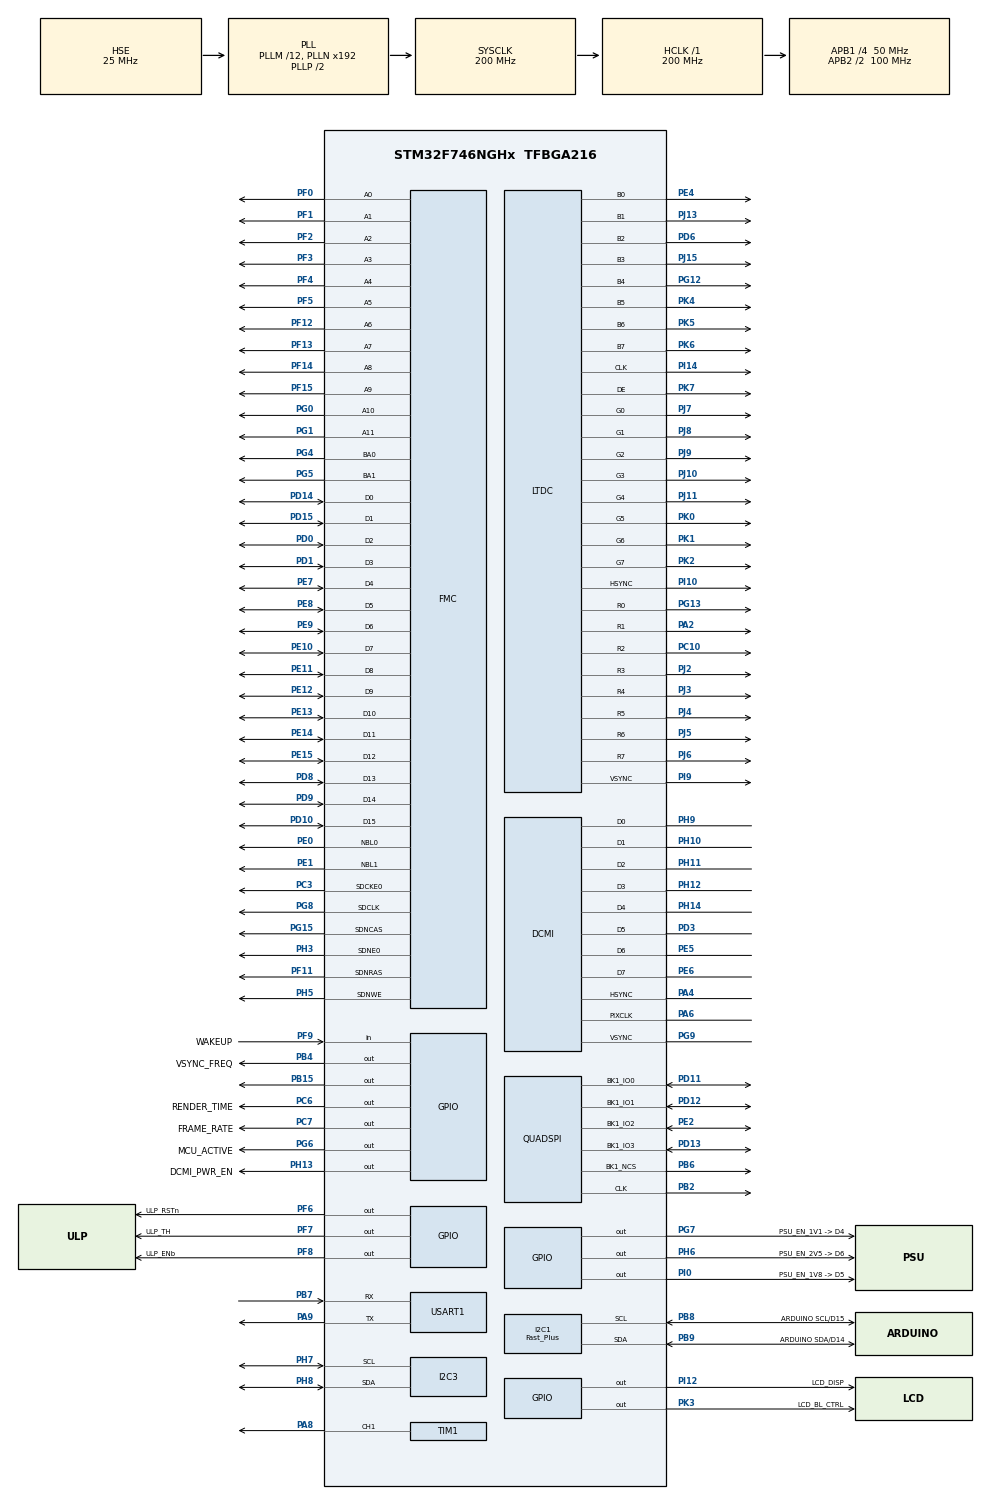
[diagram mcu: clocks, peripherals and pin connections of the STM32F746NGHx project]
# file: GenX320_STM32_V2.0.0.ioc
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CORTEX_M7.ART_ACCLERATOR_ENABLE=1
CORTEX_M7.AccessPermission-Cortex_Memory_Protection_Unit_Region0_Settings=MPU_REGION_FULL_ACCESS
CORTEX_M7.AccessPermission-Cortex_Memory_Protection_Unit_Region1_Settings=MPU_REGION_FULL_ACCESS
CORTEX_M7.BaseAddress-Cortex_Memory_Protection_Unit_Region0_Settings=0x90000000
CORTEX_M7.BaseAddress-Cortex_Memory_Protection_Unit_Region1_Settings=0x90000000
CORTEX_M7.CPU_DCache=Enabled
CORTEX_M7.CPU_ICache=Enabled
CORTEX_M7.Enable-Cortex_Memory_Protection_Unit_Region0_Settings=MPU_REGION_ENABLE
CORTEX_M7.Enable-Cortex_Memory_Protection_Unit_Region1_Settings=MPU_REGION_ENABLE
CORTEX_M7.IsCacheable-Cortex_Memory_Protection_Unit_Region1_Settings=MPU_ACCESS_CACHEABLE
CORTEX_M7.MPU_Control=MPU_PRIVILEGED_DEFAULT
CORTEX_M7.PREFETCH_ENABLE=1
CORTEX_M7.Size-Cortex_Memory_Protection_Unit_Region0_Settings=MPU_REGION_SIZE_256MB
CORTEX_M7.Size-Cortex_Memory_Protection_Unit_Region1_Settings=MPU_REGION_SIZE_16MB
DCMI.HSPolarity=DCMI_HSPOLARITY_HIGH
DCMI.JPEGMode=DCMI_JPEG_ENABLE
DCMI.VSPolarity=DCMI_VSPOLARITY_HIGH
Dma.DCMI.0.Direction=DMA_PERIPH_TO_MEMORY
Dma.DCMI.0.FIFOMode=DMA_FIFOMODE_ENABLE
Dma.DCMI.0.FIFOThreshold=DMA_FIFO_THRESHOLD_FULL
Dma.DCMI.0.Instance=DMA2_Stream1
Dma.DCMI.0.MemBurst=DMA_MBURST_INC4
Dma.DCMI.0.MemDataAlignment=DMA_MDATAALIGN_WORD
Dma.DCMI.0.MemInc=DMA_MINC_ENABLE
Dma.DCMI.0.Mode=DMA_CIRCULAR
Dma.DCMI.0.PeriphBurst=DMA_PBURST_SINGLE
Dma.DCMI.0.PeriphDataAlignment=DMA_PDATAALIGN_WORD
Dma.DCMI.0.PeriphInc=DMA_PINC_DISABLE
Dma.DCMI.0.Priority=DMA_PRIORITY_HIGH
Dma.MEMTOMEM.1.Direction=DMA_MEMORY_TO_MEMORY
Dma.MEMTOMEM.1.FIFOMode=DMA_FIFOMODE_ENABLE
Dma.MEMTOMEM.1.FIFOThreshold=DMA_FIFO_THRESHOLD_FULL
Dma.MEMTOMEM.1.Instance=DMA2_Stream0
Dma.MEMTOMEM.1.MemBurst=DMA_MBURST_INC4
Dma.MEMTOMEM.1.MemDataAlignment=DMA_MDATAALIGN_WORD
Dma.MEMTOMEM.1.MemInc=DMA_MINC_ENABLE
Dma.MEMTOMEM.1.Mode=DMA_NORMAL
Dma.MEMTOMEM.1.PeriphBurst=DMA_PBURST_INC4
Dma.MEMTOMEM.1.PeriphDataAlignment=DMA_PDATAALIGN_WORD
Dma.MEMTOMEM.1.PeriphInc=DMA_PINC_DISABLE
Dma.MEMTOMEM.1.Priority=DMA_PRIORITY_LOW
Dma.Request0=DCMI
Dma.Request1=MEMTOMEM
FMC.CASLatency1=FMC_SDRAM_CAS_LATENCY_3
FMC.ExitSelfRefreshDelay1=7
FMC.LoadToActiveDelay1=2
FMC.RCDDelay1=2
FMC.RPDelay1=2
FMC.ReadBurst1=FMC_SDRAM_RBURST_ENABLE
FMC.RowCycleDelay1=7
FMC.SDClockPeriod1=FMC_SDRAM_CLOCK_PERIOD_2
FMC.SelfRefreshTime1=4
FMC.WriteRecoveryTime1=3
FREERTOS.BinarySemaphores01=Vsync_Semaphore,Dynamic,NULL;ESP_LPW_Semph,Dynamic,NULL;Activity_Map_Semph,Dynamic,NULL;Statistics_Semph,Dynamic,NULL;Led_Tracking_Semph,Dynamic,NULL
FREERTOS.Mutexes01=tskCtlUpdateFb,Static,TskCtlUpdateFbControlBlock
FREERTOS.Tasks01=ESP_LPW,24,256,ESP_LPW_Task,Default,NULL,Dynamic,NULL,NULL;TouchGFXTask,26,4096,TouchGFX_Task,As external,NULL,Dynamic,NULL,NULL;Update_Fb,32,512,Task_Update_Fb,Default,&args_update_fb,Dynamic,NULL,NULL;Event_Decoding,27,256,Event_Decoding_Task,Default,&args_evt_decoder,Dynamic,NULL,NULL;Activity_Map,25,256,Activity_Map_Task,Default,NULL,Dynamic,NULL,NULL;Statistics,25,256,Statistics_Task,Default,NULL,Dynamic,NULL,NULL;Led_Tracking,25,256,Led_Tracking_Task,Default,NULL,Dynamic,NULL,NULL
FREERTOS.configTOTAL_HEAP_SIZE=75000
FREERTOS.configUSE_APPLICATION_TASK_TAG=1
FREERTOS.configUSE_IDLE_HOOK=0
FREERTOS.configUSE_NEWLIB_REENTRANT=1
I2C1.I2C_Speed_Mode=I2C_Fast_Plus
I2C1.Speed=1000
I2C1.Timing=0x0020081F
I2C3.Timing=0x00C0EAFF
LTDC.ActiveH=272
LTDC.ActiveW=480
LTDC.Alpha_L0=255
LTDC.Alpha_L1=255
LTDC.BlendingFactor1_L0=LTDC_BLENDING_FACTOR1_CA
LTDC.BlendingFactor1_L1=LTDC_BLENDING_FACTOR1_PAxCA
LTDC.BlendingFactor2_L0=LTDC_BLENDING_FACTOR2_CA
LTDC.BlendingFactor2_L1=LTDC_BLENDING_FACTOR2_PAxCA
LTDC.DEPolarity=LTDC_DEPOLARITY_AH
LTDC.FBStartAdress_L0=0xC0000000
LTDC.FBStartAdress_L1=(uint32_t)frame_buffer_l1_one
LTDC.Green_L1=0
LTDC.HBP=43
LTDC.HFP=8
LTDC.HSync=4
LTDC.ImageHeight_L0=272
LTDC.ImageHeight_L1=272
LTDC.ImageWidth_L0=480
LTDC.ImageWidth_L1=320
LTDC.Layers=0
LTDC.PixelFormat_L0=LTDC_PIXEL_FORMAT_ARGB8888
LTDC.VBP=12
LTDC.VFP=12
LTDC.VSPolarity=LTDC_VSPOLARITY_AH
LTDC.VSync=2
LTDC.WindowX0_L1=160
LTDC.WindowX1_L0=480
LTDC.WindowX1_L1=480
LTDC.WindowY1_L0=272
LTDC.WindowY1_L1=272
Mcu.Family=STM32F7
Mcu.Name=STM32F746NGHx
Mcu.Package=TFBGA216
NVIC.DCMI_IRQn=true\:5\:0\:false\:false\:true\:true\:true\:true\:true
NVIC.DMA2D_IRQn=true\:5\:0\:true\:false\:true\:true\:true\:true\:true
NVIC.DMA2_Stream0_IRQn=true\:5\:0\:false\:false\:true\:true\:true\:true\:true
NVIC.DMA2_Stream1_IRQn=true\:5\:0\:false\:false\:true\:true\:false\:true\:true
NVIC.I2C1_EV_IRQn=true\:5\:0\:false\:false\:true\:true\:true\:true\:true
NVIC.LTDC_ER_IRQn=true\:5\:0\:false\:false\:true\:true\:true\:true\:true
NVIC.LTDC_IRQn=true\:5\:0\:false\:false\:true\:true\:true\:true\:true
NVIC.PriorityGroup=NVIC_PRIORITYGROUP_4
NVIC.TIM6_DAC_IRQn=true\:15\:0\:false\:false\:true\:false\:false\:true\:true
NVIC.TimeBase=TIM6_DAC_IRQn
NVIC.TimeBaseIP=TIM6
NVIC.USART1_IRQn=true\:5\:0\:false\:false\:true\:true\:true\:true\:true
PA13.Mode=Serial_Wire
PA13.Signal=SYS_JTMS-SWDIO
PA14.Mode=Serial_Wire
PA14.Signal=SYS_JTCK-SWCLK
PA15.Signal=S_TIM2_CH1_ETR
PA2.Mode=RGB888
PA2.Signal=LTDC_R1
PA4.GPIO_Speed=GPIO_SPEED_FREQ_VERY_HIGH
PA4.Mode=Slave_8_bits_External_Synchro
PA4.Signal=DCMI_HSYNC
PA6.GPIO_Speed=GPIO_SPEED_FREQ_VERY_HIGH
PA6.Mode=Slave_8_bits_External_Synchro
PA6.Signal=DCMI_PIXCLK
PA8.GPIO_Speed=GPIO_SPEED_FREQ_HIGH
PA8.Signal=S_TIM1_CH1
PA9.GPIO_Speed=GPIO_SPEED_FREQ_LOW
PA9.Mode=Asynchronous
PA9.Signal=USART1_TX
PB15.Signal=GPIO_Output
PB2.Mode=Single Bank 1
PB2.Signal=QUADSPI_CLK
PB4.GPIO_Label=VSYNC_FREQ
PB4.GPIO_Speed=GPIO_SPEED_FREQ_VERY_HIGH
PB4.Signal=GPIO_Output
PB6.Mode=Single Bank 1
PB6.Signal=QUADSPI_BK1_NCS
PB7.GPIO_Speed=GPIO_SPEED_FREQ_LOW
PB7.Mode=Asynchronous
PB7.Signal=USART1_RX
PB8.GPIO_Label=ARDUINO SCL/D15
PB8.GPIO_Pu=GPIO_PULLUP
PB8.Mode=I2C
PB8.Signal=I2C1_SCL
PB9.GPIO_Label=ARDUINO SDA/D14
PB9.GPIO_Pu=GPIO_PULLUP
PB9.Mode=I2C
PB9.Signal=I2C1_SDA
PC10.Mode=RGB888
PC10.Signal=LTDC_R2
PC3.Mode=SdramChipSelect1_1
PC3.Signal=FMC_SDCKE0
PC6.GPIO_Label=RENDER_TIME
PC6.GPIO_Speed=GPIO_SPEED_FREQ_VERY_HIGH
PC6.Signal=GPIO_Output
PC7.GPIO_Label=FRAME_RATE
PC7.GPIO_Speed=GPIO_SPEED_FREQ_VERY_HIGH
PC7.Signal=GPIO_Output
PD0.Signal=FMC_D2_DA2
PD1.Signal=FMC_D3_DA3
PD10.Signal=FMC_D15_DA15
PD11.Mode=Single Bank 1
PD11.Signal=QUADSPI_BK1_IO0
PD12.Mode=Single Bank 1
PD12.Signal=QUADSPI_BK1_IO1
PD13.Mode=Single Bank 1
PD13.Signal=QUADSPI_BK1_IO3
PD14.Signal=FMC_D0_DA0
PD15.Signal=FMC_D1_DA1
PD3.GPIO_Speed=GPIO_SPEED_FREQ_VERY_HIGH
PD3.Mode=Slave_8_bits_External_Synchro
PD3.Signal=DCMI_D5
PD6.Mode=RGB888
PD6.Signal=LTDC_B2
PD8.Signal=FMC_D13_DA13
PD9.Signal=FMC_D14_DA14
PE0.Signal=FMC_NBL0
PE1.Signal=FMC_NBL1
PE10.Signal=FMC_D7_DA7
PE11.Signal=FMC_D8_DA8
PE12.Signal=FMC_D9_DA9
PE13.Signal=FMC_D10_DA10
PE14.Signal=FMC_D11_DA11
PE15.Signal=FMC_D12_DA12
PE2.Mode=Single Bank 1
PE2.Signal=QUADSPI_BK1_IO2
PE4.Mode=RGB888
PE4.Signal=LTDC_B0
PE5.GPIO_Speed=GPIO_SPEED_FREQ_VERY_HIGH
PE5.Mode=Slave_8_bits_External_Synchro
PE5.Signal=DCMI_D6
PE6.GPIO_Speed=GPIO_SPEED_FREQ_VERY_HIGH
PE6.Mode=Slave_8_bits_External_Synchro
PE6.Signal=DCMI_D7
PE7.Signal=FMC_D4_DA4
PE8.Signal=FMC_D5_DA5
PE9.Signal=FMC_D6_DA6
PF0.Signal=FMC_A0
PF1.Signal=FMC_A1
PF11.Signal=FMC_SDNRAS
PF12.Signal=FMC_A6
PF13.Signal=FMC_A7
PF14.Signal=FMC_A8
PF15.Signal=FMC_A9
PF2.Signal=FMC_A2
PF3.Signal=FMC_A3
PF4.Signal=FMC_A4
PF5.Signal=FMC_A5
PF6.GPIO_Label=ULP_RSTn
PF6.PinState=GPIO_PIN_SET
PF6.Signal=GPIO_Output
PF7.GPIO_Label=ULP_TH
PF7.PinState=GPIO_PIN_SET
PF7.Signal=GPIO_Output
PF8.GPIO_Label=ULP_ENb
PF8.PinState=GPIO_PIN_SET
PF8.Signal=GPIO_Output
PF9.GPIO_Label=WAKEUP
PF9.Signal=GPIO_Input
PG0.Signal=FMC_A10
PG1.Signal=FMC_A11
PG12.Mode=RGB888
PG12.Signal=LTDC_B4
PG13.Mode=RGB888
PG13.Signal=LTDC_R0
PG15.Signal=FMC_SDNCAS
PG4.Signal=FMC_A14_BA0
PG5.Signal=FMC_A15_BA1
PG6.GPIO_Label=MCU_ACTIVE
PG6.GPIO_Speed=GPIO_SPEED_FREQ_VERY_HIGH
PG6.Signal=GPIO_Output
PG7.GPIO_Label=PSU_EN_1V1 -> D4
PG7.Signal=GPIO_Output
PG8.Signal=FMC_SDCLK
PG9.GPIO_Speed=GPIO_SPEED_FREQ_VERY_HIGH
PG9.Mode=Slave_8_bits_External_Synchro
PG9.Signal=DCMI_VSYNC
PH0/OSC_IN.Mode=HSE-External-Oscillator
PH0/OSC_IN.Signal=RCC_OSC_IN
PH1/OSC_OUT.Mode=HSE-External-Oscillator
PH1/OSC_OUT.Signal=RCC_OSC_OUT
PH10.GPIO_Speed=GPIO_SPEED_FREQ_VERY_HIGH
PH10.Mode=Slave_8_bits_External_Synchro
PH10.Signal=DCMI_D1
PH11.GPIO_Speed=GPIO_SPEED_FREQ_VERY_HIGH
PH11.Mode=Slave_8_bits_External_Synchro
PH11.Signal=DCMI_D2
PH12.GPIO_Speed=GPIO_SPEED_FREQ_VERY_HIGH
PH12.Mode=Slave_8_bits_External_Synchro
PH12.Signal=DCMI_D3
PH13.GPIO_Label=DCMI_PWR_EN
PH13.Signal=GPIO_Output
PH14.GPIO_Speed=GPIO_SPEED_FREQ_VERY_HIGH
PH14.Mode=Slave_8_bits_External_Synchro
PH14.Signal=DCMI_D4
PH3.Mode=SdramChipSelect1_1
PH3.Signal=FMC_SDNE0
PH5.Signal=FMC_SDNWE
PH6.GPIO_Label=PSU_EN_2V5 -> D6
PH6.Signal=GPIO_Output
PH7.GPIO_Pu=GPIO_PULLUP
PH7.Mode=I2C
PH7.Signal=I2C3_SCL
PH8.GPIO_Pu=GPIO_PULLUP
PH8.Mode=I2C
PH8.Signal=I2C3_SDA
PH9.GPIO_Speed=GPIO_SPEED_FREQ_VERY_HIGH
PH9.Mode=Slave_8_bits_External_Synchro
PH9.Signal=DCMI_D0
PI0.GPIO_Label=PSU_EN_1V8 -> D5
PI0.Signal=GPIO_Output
PI10.Mode=RGB888
PI10.Signal=LTDC_HSYNC
PI12.GPIO_Label=LCD_DISP
PI12.PinState=GPIO_PIN_SET
PI12.Signal=GPIO_Output
PI14.Mode=RGB888
PI14.Signal=LTDC_CLK
PI9.Mode=RGB888
PI9.Signal=LTDC_VSYNC
PJ10.Mode=RGB888
PJ10.Signal=LTDC_G3
PJ11.Mode=RGB888
PJ11.Signal=LTDC_G4
PJ13.Mode=RGB888
PJ13.Signal=LTDC_B1
PJ15.Mode=RGB888
PJ15.Signal=LTDC_B3
PJ2.Mode=RGB888
PJ2.Signal=LTDC_R3
PJ3.Mode=RGB888
PJ3.Signal=LTDC_R4
PJ4.Mode=RGB888
PJ4.Signal=LTDC_R5
PJ5.Mode=RGB888
PJ5.Signal=LTDC_R6
PJ6.Mode=RGB888
PJ6.Signal=LTDC_R7
PJ7.Mode=RGB888
PJ7.Signal=LTDC_G0
PJ8.Mode=RGB888
PJ8.Signal=LTDC_G1
PJ9.Mode=RGB888
PJ9.Signal=LTDC_G2
PK0.Mode=RGB888
PK0.Signal=LTDC_G5
PK1.Mode=RGB888
PK1.Signal=LTDC_G6
PK2.Mode=RGB888
PK2.Signal=LTDC_G7
PK3.GPIO_Label=LCD_BL_CTRL
PK3.PinState=GPIO_PIN_SET
PK3.Signal=GPIO_Output
PK4.Mode=RGB888
PK4.Signal=LTDC_B5
PK5.Mode=RGB888
PK5.Signal=LTDC_B6
PK6.Mode=RGB888
PK6.Signal=LTDC_B7
PK7.Mode=RGB888
PK7.Signal=LTDC_DE
ProjectManager.HeapSize=0xA00
ProjectManager.StackSize=0xA00
ProjectManager.TargetToolchain=STM32CubeIDE
QUADSPI.ChipSelectHighTime=QSPI_CS_HIGH_TIME_6_CYCLE
QUADSPI.ClockPrescaler=1
QUADSPI.FifoThreshold=4
QUADSPI.FlashSize=24
QUADSPI.SampleShifting=QSPI_SAMPLE_SHIFTING_HALFCYCLE
RCC.AHBFreq_Value=200000000
RCC.APB1CLKDivider=RCC_HCLK_DIV4
RCC.APB1Freq_Value=50000000
RCC.APB1TimFreq_Value=100000000
RCC.APB2CLKDivider=RCC_HCLK_DIV2
RCC.APB2Freq_Value=100000000
RCC.APB2TimFreq_Value=200000000
RCC.CortexFreq_Value=200000000
RCC.HCLKFreq_Value=200000000
RCC.HSE_VALUE=25000000
RCC.HSI_VALUE=16000000
RCC.LSE_VALUE=32768
RCC.PLLI2SN=100
RCC.PLLM=12
RCC.PLLSAIN=50
RCC.PLLSAIRDiv=RCC_PLLSAIDIVR_4
RCC.PLLSourceVirtual=RCC_PLLSOURCE_HSE
RCC.SYSCLKFreq_VALUE=200000000
RCC.SYSCLKSource=RCC_SYSCLKSOURCE_PLLCLK
RCC.USBFreq_Value=200000000
RCC.VCOOutputFreq_Value=400000000
SH.FMC_A0.0=FMC_A0,12b-sda1
SH.FMC_A1.0=FMC_A1,12b-sda1
SH.FMC_A10.0=FMC_A10,12b-sda1
SH.FMC_A11.0=FMC_A11,12b-sda1
SH.FMC_A14_BA0.0=FMC_BA0,FourSdramBanks1
SH.FMC_A15_BA1.0=FMC_BA1,FourSdramBanks1
SH.FMC_A2.0=FMC_A2,12b-sda1
SH.FMC_A3.0=FMC_A3,12b-sda1
SH.FMC_A4.0=FMC_A4,12b-sda1
SH.FMC_A5.0=FMC_A5,12b-sda1
SH.FMC_A6.0=FMC_A6,12b-sda1
SH.FMC_A7.0=FMC_A7,12b-sda1
SH.FMC_A8.0=FMC_A8,12b-sda1
SH.FMC_A9.0=FMC_A9,12b-sda1
SH.FMC_D0_DA0.0=FMC_D0,sd-16b-d1
SH.FMC_D10_DA10.0=FMC_D10,sd-16b-d1
SH.FMC_D11_DA11.0=FMC_D11,sd-16b-d1
SH.FMC_D12_DA12.0=FMC_D12,sd-16b-d1
SH.FMC_D13_DA13.0=FMC_D13,sd-16b-d1
SH.FMC_D14_DA14.0=FMC_D14,sd-16b-d1
SH.FMC_D15_DA15.0=FMC_D15,sd-16b-d1
SH.FMC_D1_DA1.0=FMC_D1,sd-16b-d1
SH.FMC_D2_DA2.0=FMC_D2,sd-16b-d1
SH.FMC_D3_DA3.0=FMC_D3,sd-16b-d1
SH.FMC_D4_DA4.0=FMC_D4,sd-16b-d1
SH.FMC_D5_DA5.0=FMC_D5,sd-16b-d1
SH.FMC_D6_DA6.0=FMC_D6,sd-16b-d1
SH.FMC_D7_DA7.0=FMC_D7,sd-16b-d1
SH.FMC_D8_DA8.0=FMC_D8,sd-16b-d1
SH.FMC_D9_DA9.0=FMC_D9,sd-16b-d1
SH.FMC_NBL0.0=FMC_NBL0,Sd2ByteEnable1
SH.FMC_NBL1.0=FMC_NBL1,Sd2ByteEnable1
SH.FMC_SDCLK.0=FMC_SDCLK,12b-sda1
SH.FMC_SDNCAS.0=FMC_SDNCAS,12b-sda1
SH.FMC_SDNRAS.0=FMC_SDNRAS,12b-sda1
SH.FMC_SDNWE.0=FMC_SDNWE,12b-sda1
SH.S_TIM1_CH1.0=TIM1_CH1,PWM Generation1 CH1
SH.S_TIM2_CH1_ETR.0=TIM2_CH1
STMicroelectronics.X-CUBE-TOUCHGFX.4.22.1.ApplicationCcGraphicsJjApplication=TouchGFXOoGenerator
STMicroelectronics.X-CUBE-TOUCHGFX.4.22.1.tgfx_address1=0xC0000000
STMicroelectronics.X-CUBE-TOUCHGFX.4.22.1.tgfx_address2=0xC003FC00
STMicroelectronics.X-CUBE-TOUCHGFX.4.22.1.tgfx_buffering_strategy=Double
STMicroelectronics.X-CUBE-TOUCHGFX.4.22.1.tgfx_display_interface=disp_ltdc
STMicroelectronics.X-CUBE-TOUCHGFX.4.22.1.tgfx_hardware_accelerator=dma_2d
STMicroelectronics.X-CUBE-TOUCHGFX.4.22.1.tgfx_location=Allocate
STMicroelectronics.X-CUBE-TOUCHGFX.4.22.1.tgfx_vector_rendering=Disabled
STMicroelectronics.X-CUBE-TOUCHGFX.4.22.1.tgfx_video=Disabled
STMicroelectronics.X-CUBE-TOUCHGFX.4.22.1.tgfx_video_buffer_format=RGB565\:2
STMicroelectronics.X-CUBE-TOUCHGFX.4.22.1.tgfx_video_height=272
STMicroelectronics.X-CUBE-TOUCHGFX.4.22.1.tgfx_video_strategy=2
STMicroelectronics.X-CUBE-TOUCHGFX.4.22.1.tgfx_video_width=480
STMicroelectronics.X-CUBE-TOUCHGFX.4.22.1.tgfx_vsync=vsync_ltdc
TIM1.Channel-PWM\ Generation1\ CH1=TIM_CHANNEL_1
TIM1.OCFastMode_PWM-PWM\ Generation1\ CH1=TIM_OCFAST_ENABLE
TIM1.Period=9
TIM1.Prescaler=1
TIM1.Pulse-PWM\ Generation1\ CH1=5
TIM2.Period=4294967295
TIM2.Prescaler=99
USART1.VirtualMode-Asynchronous=VM_ASYNC
VP_CRC_VS_CRC.Mode=CRC_Activate
VP_DMA2D_VS_DMA2D.Mode=DMA2D_Activate
VP_FREERTOS_VS_CMSIS_V2.Mode=CMSIS_V2
VP_STMicroelectronics.X-CUBE-TOUCHGFX_VS_GraphicsJjApplication_4.22.1.Mode=GraphicsJjApplication
VP_SYS_VS_tim6.Mode=TIM6
VP_TIM1_VS_ClockSourceINT.Mode=Internal
VP_TIM2_VS_ClockSourceINT.Mode=Internal
board=custom

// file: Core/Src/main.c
/* USER CODE BEGIN Header */
/**
 ******************************************************************************
 * @file           : main.c
 * @brief          : Main program body
 ******************************************************************************
 * @attention
 *
 * <h2><center>&copy; Copyright (c) 2020 STMicroelectronics.
 * All rights reserved.</center></h2>
 *
 * This software component is licensed by ST under Ultimate Liberty license
 * SLA0044, the "License"; You may not use this file except in compliance with
 * the License. You may obtain a copy of the License at:
 *                             www.st.com/SLA0044
 *
 ******************************************************************************
 */
/* USER CODE END Header */
#include "main.h"
#include "cmsis_os.h"
#include "app_touchgfx.h"

/* USER CODE BEGIN Includes */
#include <stm32746g_discovery_qspi.h>
#include <touchgfx/hal/Config.hpp>

/* USER CODE END Includes */

typedef StaticSemaphore_t osStaticMutexDef_t;

/* USER CODE BEGIN PD */

#define REFRESH_COUNT        1835

#define SDRAM_TIMEOUT                            ((uint32_t)0xFFFF)
#define SDRAM_MODEREG_BURST_LENGTH_1             ((uint16_t)0x0000)
#define SDRAM_MODEREG_BURST_LENGTH_2             ((uint16_t)0x0001)
#define SDRAM_MODEREG_BURST_LENGTH_4             ((uint16_t)0x0002)
#define SDRAM_MODEREG_BURST_LENGTH_8             ((uint16_t)0x0004)
#define SDRAM_MODEREG_BURST_TYPE_SEQUENTIAL      ((uint16_t)0x0000)
#define SDRAM_MODEREG_BURST_TYPE_INTERLEAVED     ((uint16_t)0x0008)
#define SDRAM_MODEREG_CAS_LATENCY_2              ((uint16_t)0x0020)
#define SDRAM_MODEREG_CAS_LATENCY_3              ((uint16_t)0x0030)
#define SDRAM_MODEREG_OPERATING_MODE_STANDARD    ((uint16_t)0x0000)
#define SDRAM_MODEREG_WRITEBURST_MODE_PROGRAMMED ((uint16_t)0x0000)
#define SDRAM_MODEREG_WRITEBURST_MODE_SINGLE     ((uint16_t)0x0200)

#define PUTCHAR_PROTOTYPE int __io_putchar(int ch)
#define STATIC_HEAP_SIZE (1024)
#define ALIGN_FLOOR(addr, type) (((uint32_t)(addr)) & ~(uint32_t)(sizeof(type)-1))
#define ALIGN_CEIL(addr, type)   ALIGN_FLOOR((uint32_t)(addr) + sizeof(type) - 1, type)

/* USER CODE END PD */

CRC_HandleTypeDef hcrc;

DCMI_HandleTypeDef hdcmi;
DMA_HandleTypeDef hdma_dcmi;

DMA2D_HandleTypeDef hdma2d;

I2C_HandleTypeDef hi2c1;
I2C_HandleTypeDef hi2c3;

LTDC_HandleTypeDef hltdc;

QSPI_HandleTypeDef hqspi;

TIM_HandleTypeDef htim1;
TIM_HandleTypeDef htim2;

UART_HandleTypeDef huart1;

DMA_HandleTypeDef hdma_memtomem_dma2_stream0;
SDRAM_HandleTypeDef hsdram1;

/* Definitions for ESP_LPW */
osThreadId_t ESP_LPWHandle;
const osThreadAttr_t ESP_LPW_attributes = {
  .name = "ESP_LPW",
  .stack_size = 256 * 4,
  .priority = (osPriority_t) osPriorityNormal,
};
/* Definitions for TouchGFXTask */
osThreadId_t TouchGFXTaskHandle;
const osThreadAttr_t TouchGFXTask_attributes = {
  .name = "TouchGFXTask",
  .stack_size = 4096 * 4,
  .priority = (osPriority_t) osPriorityNormal2,
};
/* Definitions for Update_Fb */
osThreadId_t Update_FbHandle;
const osThreadAttr_t Update_Fb_attributes = {
  .name = "Update_Fb",
  .stack_size = 512 * 4,
  .priority = (osPriority_t) osPriorityAboveNormal,
};
/* Definitions for Event_Decoding */
osThreadId_t Event_DecodingHandle;
const osThreadAttr_t Event_Decoding_attributes = {
  .name = "Event_Decoding",
  .stack_size = 256 * 4,
  .priority = (osPriority_t) osPriorityNormal3,
};
/* Definitions for Activity_Map */
osThreadId_t Activity_MapHandle;
const osThreadAttr_t Activity_Map_attributes = {
  .name = "Activity_Map",
  .stack_size = 256 * 4,
  .priority = (osPriority_t) osPriorityNormal1,
};
/* Definitions for Statistics */
osThreadId_t StatisticsHandle;
const osThreadAttr_t Statistics_attributes = {
  .name = "Statistics",
  .stack_size = 256 * 4,
  .priority = (osPriority_t) osPriorityNormal1,
};
/* Definitions for Led_Tracking */
osThreadId_t Led_TrackingHandle;
const osThreadAttr_t Led_Tracking_attributes = {
  .name = "Led_Tracking",
  .stack_size = 256 * 4,
  .priority = (osPriority_t) osPriorityNormal1,
};
/* Definitions for tskCtlUpdateFb */
osMutexId_t tskCtlUpdateFbHandle;
osStaticMutexDef_t TskCtlUpdateFbControlBlock;
const osMutexAttr_t tskCtlUpdateFb_attributes = {
  .name = "tskCtlUpdateFb",
  .cb_mem = &TskCtlUpdateFbControlBlock,
  .cb_size = sizeof(TskCtlUpdateFbControlBlock),
};
/* Definitions for Vsync_Semaphore */
osSemaphoreId_t Vsync_SemaphoreHandle;
const osSemaphoreAttr_t Vsync_Semaphore_attributes = {
  .name = "Vsync_Semaphore"
};
/* Definitions for ESP_LPW_Semph */
osSemaphoreId_t ESP_LPW_SemphHandle;
const osSemaphoreAttr_t ESP_LPW_Semph_attributes = {
  .name = "ESP_LPW_Semph"
};
/* Definitions for Activity_Map_Semph */
osSemaphoreId_t Activity_Map_SemphHandle;
const osSemaphoreAttr_t Activity_Map_Semph_attributes = {
  .name = "Activity_Map_Semph"
};
/* Definitions for Statistics_Semph */
osSemaphoreId_t Statistics_SemphHandle;
const osSemaphoreAttr_t Statistics_Semph_attributes = {
  .name = "Statistics_Semph"
};
/* Definitions for Led_Tracking_Semph */
osSemaphoreId_t Led_Tracking_SemphHandle;
const osSemaphoreAttr_t Led_Tracking_Semph_attributes = {
  .name = "Led_Tracking_Semph"
};
/* USER CODE BEGIN PV */
static FMC_SDRAM_CommandTypeDef Command;

/* I2C driver */
DrvI2cHandle_t drv_i2c;

/* Dma driver */
DrvDmaHandle_t drv_dma;

/* GenX320 driver */
DrvGenx320Handle_t drv_genx320;

/* Thread arguments. */
static void* pvStaticAllocate(size_t ulSize);

const args_update_fb_t args_update_fb = {
	.hltdc = &hltdc,
	.drv_dma = &drv_dma,
};
const args_evt_decoder_t args_evt_decoder = {
		.hdcmi = &hdcmi,
		.hdma_dcmi = &hdma_dcmi,
		.drv_genx320 = &drv_genx320,
};

/* USER CODE END PV */

void SystemClock_Config(void);
static void MPU_Config(void);
static void MX_GPIO_Init(void);
static void MX_DMA_Init(void);
static void MX_FMC_Init(void);
static void MX_I2C3_Init(void);
static void MX_QUADSPI_Init(void);
static void MX_I2C1_Init(void);
static void MX_DCMI_Init(void);
static void MX_CRC_Init(void);
static void MX_LTDC_Init(void);
static void MX_USART1_UART_Init(void);
static void MX_DMA2D_Init(void);
static void MX_TIM1_Init(void);
static void MX_TIM2_Init(void);
void ESP_LPW_Task(void *argument);
extern void TouchGFX_Task(void *argument);
void Task_Update_Fb(void *argument);
void Event_Decoding_Task(void *argument);
void Activity_Map_Task(void *argument);
void Statistics_Task(void *argument);
void Led_Tracking_Task(void *argument);

/* USER CODE BEGIN PFP */

/*
* @brief  Call back function for transmission transfer complete
*/
void HAL_I2C_MasterTxCpltCallback(I2C_HandleTypeDef *hi2c)
{
	assert(hi2c == &hi2c1);
	ucDrvI2cCallback(drv_i2c);
}

/*
* @brief  Call back function for reception transfer complete
*/
void HAL_I2C_MasterRxCpltCallback(I2C_HandleTypeDef *hi2c)
{
	assert(hi2c == &hi2c1);
	ucDrvI2cCallback(drv_i2c);
}

/*
* @brief  Call back function for DMA transfer complete
*/
void HAL_DMA_MasterCpltCallback(DMA_HandleTypeDef *hdma)
{
	assert(hdma == &hdma_memtomem_dma2_stream0);
	ucDrvDmaCallback(drv_dma);

}

/*
* @brief  For Debug Communication
*/
PUTCHAR_PROTOTYPE
{
	HAL_UART_Transmit(&huart1, (uint8_t *)&ch, 1, HAL_MAX_DELAY);
	return ch;
}

/*
 * @brief Call back function for register reload
 */
void HAL_LTDC_ReloadEventCallback(LTDC_HandleTypeDef *hltdc) {
	update_fb_callback();
}

/**
 * @brief Function to reset the frame buffers which do not belong to the .bss section.
 */
void reset_buffers() {

	/* Reset the TouchGFX Frame Buffer */
	memset((void *)GUI_BUF_ADD_1 , 0x0 , 0x3fc00);
	memset((void *)GUI_BUF_ADD_2 , 0x0 , 0xff000);

}

/**
 * @brief Function to execute the power down sequence for ULP passive mode.
 */
void ULP_standby_sequence() {

	/* Toggle OFF the RSTN */
	HAL_GPIO_WritePin(GPIOB, GPIO_PIN_15, GPIO_PIN_RESET);
	psee_sleep_us_imp(tclk_stop);

	/* Stop the 10MHz PWM signal */
	HAL_TIM_PWM_Stop(&htim1,TIM_CHANNEL_1);
	psee_sleep_us_imp(Tana_stop);

	/* Switch ON PSU_EN_2V5*/
	if(HAL_GPIO_ReadPin(GPIOH, GPIO_PIN_6) != GPIO_PIN_SET) {
		HAL_GPIO_WritePin(GPIOH, GPIO_PIN_6, GPIO_PIN_SET);
		psee_sleep_us_imp(TIO_stop);
	} else {
		psee_sleep_us_imp(TIO_stop);
	}

	/* Switch OFF PSU_EN_1V8*/
	HAL_GPIO_WritePin(GPIOI, GPIO_PIN_0, GPIO_PIN_RESET);
	psee_sleep_us_imp(Tdig_stop);

	/* Switch OFF PSU_EN_1V1*/
	HAL_GPIO_WritePin(GPIOG, GPIO_PIN_7, GPIO_PIN_RESET);
	psee_sleep_us_imp(Tulp_set);

	/* Toggle OFF ULP_ENB*/
	HAL_GPIO_WritePin(GPIOF, GPIO_PIN_8, GPIO_PIN_RESET);

}

/**
 * @brief Function to execute the power up sequence for waking up from ULP passive mode.
 */
void ULP_wakeup_sequence() {
	/* Initialize the sensor */
	const struct issd *current_issd = psee_open_evt();

	/* Set Standard biases */
	psee_sensor_set_biases(&genx320_default_biases);

	/* Start the sensor */
	psee_sensor_start(current_issd);

	/* Set Flip */
	psee_sensor_set_flip(0,0);

	/* Configure the activity map */
	psee_configure_activity_map();

	/* Toggle ON ULP_ENB*/
	HAL_GPIO_WritePin(GPIOF, GPIO_PIN_8, GPIO_PIN_SET);

}

/* USER CODE END PFP */

/* USER CODE BEGIN 0 */

static uint8_t pxStaticHeap[STATIC_HEAP_SIZE] __ALIGNED(32) = {0};

/**
 * @brief Function for Static heap allocation.
 */
static void* pvStaticAllocate(size_t ulSize)
{
	static size_t ulAllocated = 0;

    /* Align requested size on long boundaries. */
    unsigned ulAlign = (unsigned) ALIGN_CEIL(ulSize, long);

    /* Check the requested size do not exceed max size. */
    size_t ulRequested = ulAllocated + ulAlign;
    if (STATIC_HEAP_SIZE < ulRequested)
        return NULL;

    /* Return the current buffer position and update the position. */
    void *pVoid = (void *) (pxStaticHeap + ulAllocated);
    ulAllocated = ulRequested;
    return pVoid;
}

/* USER CODE END 0 */

int main(void)
{
  /* USER CODE BEGIN 1 */

	/* PUT THIS FIRST, WON'T WORK OTHERWISE */
	MX_DMA_Init();

  /* USER CODE END 1 */

  /* MPU Configuration--------------------------------------------------------*/
  MPU_Config();
/* Enable the CPU Cache */

  /* Enable I-Cache---------------------------------------------------------*/
  SCB_EnableICache();

  /* Enable D-Cache---------------------------------------------------------*/
  SCB_EnableDCache();

  /* MCU Configuration--------------------------------------------------------*/

  /* Reset of all peripherals, Initializes the Flash interface and the Systick. */
  HAL_Init();

  /* Configure the system clock */
  SystemClock_Config();

  /* Initialize all configured peripherals */
  MX_GPIO_Init();
  MX_DMA_Init();
  MX_FMC_Init();
  MX_I2C3_Init();
  MX_QUADSPI_Init();
  MX_I2C1_Init();
  MX_DCMI_Init();
  MX_CRC_Init();
  MX_LTDC_Init();
  MX_USART1_UART_Init();
  MX_DMA2D_Init();
  MX_TIM1_Init();
  MX_TIM2_Init();
  MX_TouchGFX_Init();
  /* Call PreOsInit function */
  MX_TouchGFX_PreOSInit();
  /* USER CODE BEGIN 2 */

  /* Change Systick priority to 4 to use HAL_DELAY() */
  HAL_InitTick(4);

  /* Reset the display frame buffers */
  reset_buffers();
  reset_frame_buffers();

  /* Initialize drivers */
  BaseType_t i2c_status =  xDrvI2cCreate(&hi2c1, pvStaticAllocate, &drv_i2c);
  assert(i2c_status == pdTRUE);

  BaseType_t dma_status =  xDrvDmaCreate(&hdma_memtomem_dma2_stream0, pvStaticAllocate, &drv_dma);
  assert(dma_status == pdTRUE);
  HAL_DMA_RegisterCallback(&hdma_memtomem_dma2_stream0, HAL_DMA_XFER_CPLT_CB_ID, HAL_DMA_MasterCpltCallback);

  BaseType_t genx320_status =  xDrvGenx320Create(pvStaticAllocate, &drv_genx320);
  assert(genx320_status == pdTRUE);

  /* Change Systick priority back to 15 */
  HAL_InitTick(15);

  /* USER CODE END 2 */

  /* Init scheduler */
  osKernelInitialize();
  /* Create the mutex(es) */
  /* creation of tskCtlUpdateFb */
  tskCtlUpdateFbHandle = osMutexNew(&tskCtlUpdateFb_attributes);

  /* Create the semaphores(s) */
  /* creation of Vsync_Semaphore */
  Vsync_SemaphoreHandle = osSemaphoreNew(1, 0, &Vsync_Semaphore_attributes);

  /* creation of ESP_LPW_Semph */
  ESP_LPW_SemphHandle = osSemaphoreNew(1, 0, &ESP_LPW_Semph_attributes);

  /* creation of Activity_Map_Semph */
  Activity_Map_SemphHandle = osSemaphoreNew(1, 0, &Activity_Map_Semph_attributes);

  /* creation of Statistics_Semph */
  Statistics_SemphHandle = osSemaphoreNew(1, 0, &Statistics_Semph_attributes);

  /* creation of Led_Tracking_Semph */
  Led_Tracking_SemphHandle = osSemaphoreNew(1, 0, &Led_Tracking_Semph_attributes);

  /* Create the thread(s) */
  /* creation of ESP_LPW */
  ESP_LPWHandle = osThreadNew(ESP_LPW_Task, NULL, &ESP_LPW_attributes);

  /* creation of TouchGFXTask */
  TouchGFXTaskHandle = osThreadNew(TouchGFX_Task, NULL, &TouchGFXTask_attributes);

  /* creation of Update_Fb */
  Update_FbHandle = osThreadNew(Task_Update_Fb, (void*) &args_update_fb, &Update_Fb_attributes);

  /* creation of Event_Decoding */
  Event_DecodingHandle = osThreadNew(Event_Decoding_Task, (void*) &args_evt_decoder, &Event_Decoding_attributes);

  /* creation of Activity_Map */
  Activity_MapHandle = osThreadNew(Activity_Map_Task, NULL, &Activity_Map_attributes);

  /* creation of Statistics */
  StatisticsHandle = osThreadNew(Statistics_Task, NULL, &Statistics_attributes);

  /* creation of Led_Tracking */
  Led_TrackingHandle = osThreadNew(Led_Tracking_Task, NULL, &Led_Tracking_attributes);

  /* Start scheduler */
  osKernelStart();

  /* We should never get here as control is now taken by the scheduler */
  /* Infinite loop */
	while (1)
	{

	}
}

void SystemClock_Config(void)
{
  RCC_OscInitTypeDef RCC_OscInitStruct = {0};
  RCC_ClkInitTypeDef RCC_ClkInitStruct = {0};

  /** Configure the main internal regulator output voltage
  */
  __HAL_RCC_PWR_CLK_ENABLE();
  __HAL_PWR_VOLTAGESCALING_CONFIG(PWR_REGULATOR_VOLTAGE_SCALE1);

  /** Initializes the RCC Oscillators according to the specified parameters
  * in the RCC_OscInitTypeDef structure.
  */
  RCC_OscInitStruct.OscillatorType = RCC_OSCILLATORTYPE_HSE;
  RCC_OscInitStruct.HSEState = RCC_HSE_ON;
  RCC_OscInitStruct.PLL.PLLState = RCC_PLL_ON;
  RCC_OscInitStruct.PLL.PLLSource = RCC_PLLSOURCE_HSE;
  RCC_OscInitStruct.PLL.PLLM = 12;
  RCC_OscInitStruct.PLL.PLLN = 192;
  RCC_OscInitStruct.PLL.PLLP = RCC_PLLP_DIV2;
  RCC_OscInitStruct.PLL.PLLQ = 2;
  if (HAL_RCC_OscConfig(&RCC_OscInitStruct) != HAL_OK)
  {
    Error_Handler();
  }

  /** Activate the Over-Drive mode
  */
  if (HAL_PWREx_EnableOverDrive() != HAL_OK)
  {
    Error_Handler();
  }

  /** Initializes the CPU, AHB and APB buses clocks
  */
  RCC_ClkInitStruct.ClockType = RCC_CLOCKTYPE_HCLK|RCC_CLOCKTYPE_SYSCLK
                              |RCC_CLOCKTYPE_PCLK1|RCC_CLOCKTYPE_PCLK2;
  RCC_ClkInitStruct.SYSCLKSource = RCC_SYSCLKSOURCE_PLLCLK;
  RCC_ClkInitStruct.AHBCLKDivider = RCC_SYSCLK_DIV1;
  RCC_ClkInitStruct.APB1CLKDivider = RCC_HCLK_DIV4;
  RCC_ClkInitStruct.APB2CLKDivider = RCC_HCLK_DIV2;

  if (HAL_RCC_ClockConfig(&RCC_ClkInitStruct, FLASH_LATENCY_6) != HAL_OK)
  {
    Error_Handler();
  }
}

static void MX_CRC_Init(void)
{

  hcrc.Instance = CRC;
  hcrc.Init.DefaultPolynomialUse = DEFAULT_POLYNOMIAL_ENABLE;
  hcrc.Init.DefaultInitValueUse = DEFAULT_INIT_VALUE_ENABLE;
  hcrc.Init.InputDataInversionMode = CRC_INPUTDATA_INVERSION_NONE;
  hcrc.Init.OutputDataInversionMode = CRC_OUTPUTDATA_INVERSION_DISABLE;
  hcrc.InputDataFormat = CRC_INPUTDATA_FORMAT_BYTES;
  if (HAL_CRC_Init(&hcrc) != HAL_OK)
  {
    Error_Handler();
  }

}

static void MX_DCMI_Init(void)
{

  hdcmi.Instance = DCMI;
  hdcmi.Init.SynchroMode = DCMI_SYNCHRO_HARDWARE;
  hdcmi.Init.PCKPolarity = DCMI_PCKPOLARITY_FALLING;
  hdcmi.Init.VSPolarity = DCMI_VSPOLARITY_HIGH;
  hdcmi.Init.HSPolarity = DCMI_HSPOLARITY_HIGH;
  hdcmi.Init.CaptureRate = DCMI_CR_ALL_FRAME;
  hdcmi.Init.ExtendedDataMode = DCMI_EXTEND_DATA_8B;
  hdcmi.Init.JPEGMode = DCMI_JPEG_ENABLE;
  hdcmi.Init.ByteSelectMode = DCMI_BSM_ALL;
  hdcmi.Init.ByteSelectStart = DCMI_OEBS_ODD;
  hdcmi.Init.LineSelectMode = DCMI_LSM_ALL;
  hdcmi.Init.LineSelectStart = DCMI_OELS_ODD;
  if (HAL_DCMI_Init(&hdcmi) != HAL_OK)
  {
    Error_Handler();
  }

}

static void MX_DMA2D_Init(void)
{

  hdma2d.Instance = DMA2D;
  hdma2d.Init.Mode = DMA2D_M2M;
  hdma2d.Init.ColorMode = DMA2D_OUTPUT_ARGB8888;
  hdma2d.Init.OutputOffset = 0;
  hdma2d.LayerCfg[1].InputOffset = 0;
  hdma2d.LayerCfg[1].InputColorMode = DMA2D_INPUT_ARGB8888;
  hdma2d.LayerCfg[1].AlphaMode = DMA2D_NO_MODIF_ALPHA;
  hdma2d.LayerCfg[1].InputAlpha = 0;
  if (HAL_DMA2D_Init(&hdma2d) != HAL_OK)
  {
    Error_Handler();
  }
  if (HAL_DMA2D_ConfigLayer(&hdma2d, 1) != HAL_OK)
  {
    Error_Handler();
  }

}

static void MX_I2C1_Init(void)
{

  hi2c1.Instance = I2C1;
  hi2c1.Init.Timing = 0x0020081F;
  hi2c1.Init.OwnAddress1 = 0;
  hi2c1.Init.AddressingMode = I2C_ADDRESSINGMODE_7BIT;
  hi2c1.Init.DualAddressMode = I2C_DUALADDRESS_DISABLE;
  hi2c1.Init.OwnAddress2 = 0;
  hi2c1.Init.OwnAddress2Masks = I2C_OA2_NOMASK;
  hi2c1.Init.GeneralCallMode = I2C_GENERALCALL_DISABLE;
  hi2c1.Init.NoStretchMode = I2C_NOSTRETCH_DISABLE;
  if (HAL_I2C_Init(&hi2c1) != HAL_OK)
  {
    Error_Handler();
  }

  /** Configure Analogue filter
  */
  if (HAL_I2CEx_ConfigAnalogFilter(&hi2c1, I2C_ANALOGFILTER_ENABLE) != HAL_OK)
  {
    Error_Handler();
  }

  /** Configure Digital filter
  */
  if (HAL_I2CEx_ConfigDigitalFilter(&hi2c1, 0) != HAL_OK)
  {
    Error_Handler();
  }

  /** I2C Enable Fast Mode Plus
  */
  HAL_I2CEx_EnableFastModePlus(I2C_FASTMODEPLUS_I2C1);

}

static void MX_I2C3_Init(void)
{

  /* USER CODE BEGIN I2C3_Init 0 */
	HAL_Delay(100); //Delay to fix initialization issue on some boards
  /* USER CODE END I2C3_Init 0 */

  hi2c3.Instance = I2C3;
  hi2c3.Init.Timing = 0x00C0EAFF;
  hi2c3.Init.OwnAddress1 = 0;
  hi2c3.Init.AddressingMode = I2C_ADDRESSINGMODE_7BIT;
  hi2c3.Init.DualAddressMode = I2C_DUALADDRESS_DISABLE;
  hi2c3.Init.OwnAddress2 = 0;
  hi2c3.Init.OwnAddress2Masks = I2C_OA2_NOMASK;
  hi2c3.Init.GeneralCallMode = I2C_GENERALCALL_DISABLE;
  hi2c3.Init.NoStretchMode = I2C_NOSTRETCH_DISABLE;
  if (HAL_I2C_Init(&hi2c3) != HAL_OK)
  {
    Error_Handler();
  }

  /** Configure Analogue filter
  */
  if (HAL_I2CEx_ConfigAnalogFilter(&hi2c3, I2C_ANALOGFILTER_ENABLE) != HAL_OK)
  {
    Error_Handler();
  }

  /** Configure Digital filter
  */
  if (HAL_I2CEx_ConfigDigitalFilter(&hi2c3, 0) != HAL_OK)
  {
    Error_Handler();
  }

}

static void MX_LTDC_Init(void)
{

  LTDC_LayerCfgTypeDef pLayerCfg = {0};

  hltdc.Instance = LTDC;
  hltdc.Init.HSPolarity = LTDC_HSPOLARITY_AL;
  hltdc.Init.VSPolarity = LTDC_VSPOLARITY_AH;
  hltdc.Init.DEPolarity = LTDC_DEPOLARITY_AH;
  hltdc.Init.PCPolarity = LTDC_PCPOLARITY_IPC;
  hltdc.Init.HorizontalSync = 3;
  hltdc.Init.VerticalSync = 1;
  hltdc.Init.AccumulatedHBP = 46;
  hltdc.Init.AccumulatedVBP = 13;
  hltdc.Init.AccumulatedActiveW = 526;
  hltdc.Init.AccumulatedActiveH = 285;
  hltdc.Init.TotalWidth = 534;
  hltdc.Init.TotalHeigh = 297;
  hltdc.Init.Backcolor.Blue = 0;
  hltdc.Init.Backcolor.Green = 0;
  hltdc.Init.Backcolor.Red = 0;
  if (HAL_LTDC_Init(&hltdc) != HAL_OK)
  {
    Error_Handler();
  }
  pLayerCfg.WindowX0 = 0;
  pLayerCfg.WindowX1 = 480;
  pLayerCfg.WindowY0 = 0;
  pLayerCfg.WindowY1 = 272;
  pLayerCfg.PixelFormat = LTDC_PIXEL_FORMAT_ARGB8888;
  pLayerCfg.Alpha = 255;
  pLayerCfg.Alpha0 = 0;
  pLayerCfg.BlendingFactor1 = LTDC_BLENDING_FACTOR1_CA;
  pLayerCfg.BlendingFactor2 = LTDC_BLENDING_FACTOR2_CA;
  pLayerCfg.FBStartAdress = 0xC0000000;
  pLayerCfg.ImageWidth = 480;
  pLayerCfg.ImageHeight = 272;
  pLayerCfg.Backcolor.Blue = 0;
  pLayerCfg.Backcolor.Green = 0;
  pLayerCfg.Backcolor.Red = 0;
  if (HAL_LTDC_ConfigLayer(&hltdc, &pLayerCfg, 0) != HAL_OK)
  {
    Error_Handler();
  }
  /* USER CODE BEGIN LTDC_Init 2 */

	__HAL_LTDC_DISABLE_IT(&hltdc, LTDC_IT_TE | LTDC_IT_FU);

  /* USER CODE END LTDC_Init 2 */

}

static void MX_QUADSPI_Init(void)
{

  /* QUADSPI parameter configuration*/
  hqspi.Instance = QUADSPI;
  hqspi.Init.ClockPrescaler = 1;
  hqspi.Init.FifoThreshold = 4;
  hqspi.Init.SampleShifting = QSPI_SAMPLE_SHIFTING_HALFCYCLE;
  hqspi.Init.FlashSize = 24;
  hqspi.Init.ChipSelectHighTime = QSPI_CS_HIGH_TIME_6_CYCLE;
  hqspi.Init.ClockMode = QSPI_CLOCK_MODE_0;
  hqspi.Init.FlashID = QSPI_FLASH_ID_1;
  hqspi.Init.DualFlash = QSPI_DUALFLASH_DISABLE;
  if (HAL_QSPI_Init(&hqspi) != HAL_OK)
  {
    Error_Handler();
  }
  /* USER CODE BEGIN QUADSPI_Init 2 */
	BSP_QSPI_Init();

	BSP_QSPI_MemoryMappedMode();
	HAL_NVIC_DisableIRQ(QUADSPI_IRQn);
  /* USER CODE END QUADSPI_Init 2 */

}

static void MX_TIM1_Init(void)
{

  TIM_ClockConfigTypeDef sClockSourceConfig = {0};
  TIM_MasterConfigTypeDef sMasterConfig = {0};
  TIM_OC_InitTypeDef sConfigOC = {0};
  TIM_BreakDeadTimeConfigTypeDef sBreakDeadTimeConfig = {0};

  htim1.Instance = TIM1;
  htim1.Init.Prescaler = 1;
  htim1.Init.CounterMode = TIM_COUNTERMODE_UP;
  htim1.Init.Period = 9;
  htim1.Init.ClockDivision = TIM_CLOCKDIVISION_DIV1;
  htim1.Init.RepetitionCounter = 0;
  htim1.Init.AutoReloadPreload = TIM_AUTORELOAD_PRELOAD_DISABLE;
  if (HAL_TIM_Base_Init(&htim1) != HAL_OK)
  {
    Error_Handler();
  }
  sClockSourceConfig.ClockSource = TIM_CLOCKSOURCE_INTERNAL;
  if (HAL_TIM_ConfigClockSource(&htim1, &sClockSourceConfig) != HAL_OK)
  {
    Error_Handler();
  }
  if (HAL_TIM_PWM_Init(&htim1) != HAL_OK)
  {
    Error_Handler();
  }
  sMasterConfig.MasterOutputTrigger = TIM_TRGO_RESET;
  sMasterConfig.MasterOutputTrigger2 = TIM_TRGO2_RESET;
  sMasterConfig.MasterSlaveMode = TIM_MASTERSLAVEMODE_DISABLE;
  if (HAL_TIMEx_MasterConfigSynchronization(&htim1, &sMasterConfig) != HAL_OK)
  {
    Error_Handler();
  }
  sConfigOC.OCMode = TIM_OCMODE_PWM1;
  sConfigOC.Pulse = 5;
  sConfigOC.OCPolarity = TIM_OCPOLARITY_HIGH;
  sConfigOC.OCNPolarity = TIM_OCNPOLARITY_HIGH;
  sConfigOC.OCFastMode = TIM_OCFAST_ENABLE;
  sConfigOC.OCIdleState = TIM_OCIDLESTATE_RESET;
  sConfigOC.OCNIdleState = TIM_OCNIDLESTATE_RESET;
  if (HAL_TIM_PWM_ConfigChannel(&htim1, &sConfigOC, TIM_CHANNEL_1) != HAL_OK)
  {
    Error_Handler();
  }
  sBreakDeadTimeConfig.OffStateRunMode = TIM_OSSR_DISABLE;
  sBreakDeadTimeConfig.OffStateIDLEMode = TIM_OSSI_DISABLE;
  sBreakDeadTimeConfig.LockLevel = TIM_LOCKLEVEL_OFF;
  sBreakDeadTimeConfig.DeadTime = 0;
  sBreakDeadTimeConfig.BreakState = TIM_BREAK_DISABLE;
  sBreakDeadTimeConfig.BreakPolarity = TIM_BREAKPOLARITY_HIGH;
  sBreakDeadTimeConfig.BreakFilter = 0;
  sBreakDeadTimeConfig.Break2State = TIM_BREAK2_DISABLE;
  sBreakDeadTimeConfig.Break2Polarity = TIM_BREAK2POLARITY_HIGH;
  sBreakDeadTimeConfig.Break2Filter = 0;
  sBreakDeadTimeConfig.AutomaticOutput = TIM_AUTOMATICOUTPUT_DISABLE;
  if (HAL_TIMEx_ConfigBreakDeadTime(&htim1, &sBreakDeadTimeConfig) != HAL_OK)
  {
    Error_Handler();
  }
  HAL_TIM_MspPostInit(&htim1);

}

static void MX_TIM2_Init(void)
{

  TIM_ClockConfigTypeDef sClockSourceConfig = {0};
  TIM_MasterConfigTypeDef sMasterConfig = {0};

  htim2.Instance = TIM2;
  htim2.Init.Prescaler = 99;
  htim2.Init.CounterMode = TIM_COUNTERMODE_UP;
  htim2.Init.Period = 4294967295;
  htim2.Init.ClockDivision = TIM_CLOCKDIVISION_DIV1;
  htim2.Init.AutoReloadPreload = TIM_AUTORELOAD_PRELOAD_DISABLE;
  if (HAL_TIM_Base_Init(&htim2) != HAL_OK)
  {
    Error_Handler();
  }
  sClockSourceConfig.ClockSource = TIM_CLOCKSOURCE_INTERNAL;
  if (HAL_TIM_ConfigClockSource(&htim2, &sClockSourceConfig) != HAL_OK)
  {
    Error_Handler();
  }
  sMasterConfig.MasterOutputTrigger = TIM_TRGO_RESET;
  sMasterConfig.MasterSlaveMode = TIM_MASTERSLAVEMODE_DISABLE;
  if (HAL_TIMEx_MasterConfigSynchronization(&htim2, &sMasterConfig) != HAL_OK)
  {
    Error_Handler();
  }
  /* USER CODE BEGIN TIM2_Init 2 */

  /* Start the Timer 2 for us delay function */
  HAL_TIM_Base_Start(&htim2);

  /* USER CODE END TIM2_Init 2 */

}

static void MX_USART1_UART_Init(void)
{

  huart1.Instance = USART1;
  huart1.Init.BaudRate = 115200;
  huart1.Init.WordLength = UART_WORDLENGTH_8B;
  huart1.Init.StopBits = UART_STOPBITS_1;
  huart1.Init.Parity = UART_PARITY_NONE;
  huart1.Init.Mode = UART_MODE_TX_RX;
  huart1.Init.HwFlowCtl = UART_HWCONTROL_NONE;
  huart1.Init.OverSampling = UART_OVERSAMPLING_16;
  huart1.Init.OneBitSampling = UART_ONE_BIT_SAMPLE_DISABLE;
  huart1.AdvancedInit.AdvFeatureInit = UART_ADVFEATURE_NO_INIT;
  if (HAL_UART_Init(&huart1) != HAL_OK)
  {
    Error_Handler();
  }

}

static void MX_DMA_Init(void)
{

  /* DMA controller clock enable */
  __HAL_RCC_DMA2_CLK_ENABLE();

  /* Configure DMA request hdma_memtomem_dma2_stream0 on DMA2_Stream0 */
  hdma_memtomem_dma2_stream0.Instance = DMA2_Stream0;
  hdma_memtomem_dma2_stream0.Init.Channel = DMA_CHANNEL_0;
  hdma_memtomem_dma2_stream0.Init.Direction = DMA_MEMORY_TO_MEMORY;
  hdma_memtomem_dma2_stream0.Init.PeriphInc = DMA_PINC_DISABLE;
  hdma_memtomem_dma2_stream0.Init.MemInc = DMA_MINC_ENABLE;
  hdma_memtomem_dma2_stream0.Init.PeriphDataAlignment = DMA_PDATAALIGN_WORD;
  hdma_memtomem_dma2_stream0.Init.MemDataAlignment = DMA_MDATAALIGN_WORD;
  hdma_memtomem_dma2_stream0.Init.Mode = DMA_NORMAL;
  hdma_memtomem_dma2_stream0.Init.Priority = DMA_PRIORITY_LOW;
  hdma_memtomem_dma2_stream0.Init.FIFOMode = DMA_FIFOMODE_ENABLE;
  hdma_memtomem_dma2_stream0.Init.FIFOThreshold = DMA_FIFO_THRESHOLD_FULL;
  hdma_memtomem_dma2_stream0.Init.MemBurst = DMA_MBURST_INC4;
  hdma_memtomem_dma2_stream0.Init.PeriphBurst = DMA_PBURST_INC4;
  if (HAL_DMA_Init(&hdma_memtomem_dma2_stream0) != HAL_OK)
  {
    Error_Handler( );
  }

  /* DMA interrupt init */
  /* DMA2_Stream0_IRQn interrupt configuration */
  HAL_NVIC_SetPriority(DMA2_Stream0_IRQn, 5, 0);
  HAL_NVIC_EnableIRQ(DMA2_Stream0_IRQn);
  /* DMA2_Stream1_IRQn interrupt configuration */
  HAL_NVIC_SetPriority(DMA2_Stream1_IRQn, 5, 0);
  HAL_NVIC_EnableIRQ(DMA2_Stream1_IRQn);

}

/* FMC initialization function */
static void MX_FMC_Init(void)
{

  FMC_SDRAM_TimingTypeDef SdramTiming = {0};

  /** Perform the SDRAM1 memory initialization sequence
  */
  hsdram1.Instance = FMC_SDRAM_DEVICE;
  /* hsdram1.Init */
  hsdram1.Init.SDBank = FMC_SDRAM_BANK1;
  hsdram1.Init.ColumnBitsNumber = FMC_SDRAM_COLUMN_BITS_NUM_8;
  hsdram1.Init.RowBitsNumber = FMC_SDRAM_ROW_BITS_NUM_12;
  hsdram1.Init.MemoryDataWidth = FMC_SDRAM_MEM_BUS_WIDTH_16;
  hsdram1.Init.InternalBankNumber = FMC_SDRAM_INTERN_BANKS_NUM_4;
  hsdram1.Init.CASLatency = FMC_SDRAM_CAS_LATENCY_3;
  hsdram1.Init.WriteProtection = FMC_SDRAM_WRITE_PROTECTION_DISABLE;
  hsdram1.Init.SDClockPeriod = FMC_SDRAM_CLOCK_PERIOD_2;
  hsdram1.Init.ReadBurst = FMC_SDRAM_RBURST_ENABLE;
  hsdram1.Init.ReadPipeDelay = FMC_SDRAM_RPIPE_DELAY_0;
  /* SdramTiming */
  SdramTiming.LoadToActiveDelay = 2;
  SdramTiming.ExitSelfRefreshDelay = 7;
  SdramTiming.SelfRefreshTime = 4;
  SdramTiming.RowCycleDelay = 7;
  SdramTiming.WriteRecoveryTime = 3;
  SdramTiming.RPDelay = 2;
  SdramTiming.RCDDelay = 2;

  if (HAL_SDRAM_Init(&hsdram1, &SdramTiming) != HAL_OK)
  {
    Error_Handler( );
  }

  /* USER CODE BEGIN FMC_Init 2 */
	__IO uint32_t tmpmrd = 0;

	/* Step 1: Configure a clock configuration enable command */
	Command.CommandMode            = FMC_SDRAM_CMD_CLK_ENABLE;
	Command.CommandTarget          =  FMC_SDRAM_CMD_TARGET_BANK1;
	Command.AutoRefreshNumber      = 1;
	Command.ModeRegisterDefinition = 0;

	/* Send the command */
	HAL_SDRAM_SendCommand(&hsdram1, &Command, SDRAM_TIMEOUT);

	/* Step 2: Insert 100 us minimum delay */
	/* Inserted delay is equal to 1 ms due to systick time base unit (ms) */
	HAL_Delay(1);

	/* Step 3: Configure a PALL (precharge all) command */
	Command.CommandMode            = FMC_SDRAM_CMD_PALL;
	Command.CommandTarget          = FMC_SDRAM_CMD_TARGET_BANK1;
	Command.AutoRefreshNumber      = 1;
	Command.ModeRegisterDefinition = 0;

	/* Send the command */
	HAL_SDRAM_SendCommand(&hsdram1, &Command, SDRAM_TIMEOUT);

	/* Step 4: Configure an Auto Refresh command */
	Command.CommandMode            = FMC_SDRAM_CMD_AUTOREFRESH_MODE;
	Command.CommandTarget          = FMC_SDRAM_CMD_TARGET_BANK1;
	Command.AutoRefreshNumber      = 8;
	Command.ModeRegisterDefinition = 0;

	/* Send the command */
	HAL_SDRAM_SendCommand(&hsdram1, &Command, SDRAM_TIMEOUT);

	/* Step 5: Program the external memory mode register */
	tmpmrd = (uint32_t)SDRAM_MODEREG_BURST_LENGTH_1 | \
			SDRAM_MODEREG_BURST_TYPE_SEQUENTIAL    | \
			SDRAM_MODEREG_CAS_LATENCY_3            | \
			SDRAM_MODEREG_OPERATING_MODE_STANDARD  | \
			SDRAM_MODEREG_WRITEBURST_MODE_SINGLE;

	Command.CommandMode            = FMC_SDRAM_CMD_LOAD_MODE;
	Command.CommandTarget          = FMC_SDRAM_CMD_TARGET_BANK1;
	Command.AutoRefreshNumber      = 1;
	Command.ModeRegisterDefinition = tmpmrd;

	/* Send the command */
	HAL_SDRAM_SendCommand(&hsdram1, &Command, SDRAM_TIMEOUT);

	/* Step 6: Set the refresh rate counter */
	/* Set the device refresh rate */
	HAL_SDRAM_ProgramRefreshRate(&hsdram1, REFRESH_COUNT);

	//Deactivate speculative/cache access to first FMC Bank to save FMC bandwidth
	FMC_Bank1->BTCR[0] = 0x000030D2;
  /* USER CODE END FMC_Init 2 */
}

static void MX_GPIO_Init(void)
{
  GPIO_InitTypeDef GPIO_InitStruct = {0};

  /* GPIO Ports Clock Enable */
  __HAL_RCC_GPIOE_CLK_ENABLE();
  __HAL_RCC_GPIOB_CLK_ENABLE();
  __HAL_RCC_GPIOA_CLK_ENABLE();
  __HAL_RCC_GPIOG_CLK_ENABLE();
  __HAL_RCC_GPIOJ_CLK_ENABLE();
  __HAL_RCC_GPIOD_CLK_ENABLE();
  __HAL_RCC_GPIOC_CLK_ENABLE();
  __HAL_RCC_GPIOK_CLK_ENABLE();
  __HAL_RCC_GPIOF_CLK_ENABLE();
  __HAL_RCC_GPIOI_CLK_ENABLE();
  __HAL_RCC_GPIOH_CLK_ENABLE();

  /*Configure GPIO pin Output Level */
  HAL_GPIO_WritePin(GPIOB, VSYNC_FREQ_Pin|GPIO_PIN_15, GPIO_PIN_RESET);

  /*Configure GPIO pin Output Level */
  HAL_GPIO_WritePin(LCD_BL_CTRL_GPIO_Port, LCD_BL_CTRL_Pin, GPIO_PIN_SET);

  /*Configure GPIO pin Output Level */
  HAL_GPIO_WritePin(LCD_DISP_GPIO_Port, LCD_DISP_Pin, GPIO_PIN_SET);

  /*Configure GPIO pin Output Level */
  HAL_GPIO_WritePin(GPIOH, DCMI_PWR_EN_Pin|PSU_EN_2V5____D6_Pin, GPIO_PIN_RESET);

  /*Configure GPIO pin Output Level */
  HAL_GPIO_WritePin(PSU_EN_1V8____D5_GPIO_Port, PSU_EN_1V8____D5_Pin, GPIO_PIN_RESET);

  /*Configure GPIO pin Output Level */
  HAL_GPIO_WritePin(GPIOC, FRAME_RATE_Pin|RENDER_TIME_Pin, GPIO_PIN_RESET);

  /*Configure GPIO pin Output Level */
  HAL_GPIO_WritePin(GPIOG, PSU_EN_1V1____D4_Pin|MCU_ACTIVE_Pin, GPIO_PIN_RESET);

  /*Configure GPIO pin Output Level */
  HAL_GPIO_WritePin(GPIOF, ULP_TH_Pin|ULP_RSTn_Pin|ULP_ENb_Pin, GPIO_PIN_SET);

  /*Configure GPIO pin : VSYNC_FREQ_Pin */
  GPIO_InitStruct.Pin = VSYNC_FREQ_Pin;
  GPIO_InitStruct.Mode = GPIO_MODE_OUTPUT_PP;
  GPIO_InitStruct.Pull = GPIO_NOPULL;
  GPIO_InitStruct.Speed = GPIO_SPEED_FREQ_VERY_HIGH;
  HAL_GPIO_Init(VSYNC_FREQ_GPIO_Port, &GPIO_InitStruct);

  /*Configure GPIO pin : LCD_BL_CTRL_Pin */
  GPIO_InitStruct.Pin = LCD_BL_CTRL_Pin;
  GPIO_InitStruct.Mode = GPIO_MODE_OUTPUT_PP;
  GPIO_InitStruct.Pull = GPIO_NOPULL;
  GPIO_InitStruct.Speed = GPIO_SPEED_FREQ_LOW;
  HAL_GPIO_Init(LCD_BL_CTRL_GPIO_Port, &GPIO_InitStruct);

  /*Configure GPIO pins : LCD_DISP_Pin PSU_EN_1V8____D5_Pin */
  GPIO_InitStruct.Pin = LCD_DISP_Pin|PSU_EN_1V8____D5_Pin;
  GPIO_InitStruct.Mode = GPIO_MODE_OUTPUT_PP;
  GPIO_InitStruct.Pull = GPIO_NOPULL;
  GPIO_InitStruct.Speed = GPIO_SPEED_FREQ_LOW;
  HAL_GPIO_Init(GPIOI, &GPIO_InitStruct);

  /*Configure GPIO pins : DCMI_PWR_EN_Pin PSU_EN_2V5____D6_Pin */
  GPIO_InitStruct.Pin = DCMI_PWR_EN_Pin|PSU_EN_2V5____D6_Pin;
  GPIO_InitStruct.Mode = GPIO_MODE_OUTPUT_PP;
  GPIO_InitStruct.Pull = GPIO_NOPULL;
  GPIO_InitStruct.Speed = GPIO_SPEED_FREQ_LOW;
  HAL_GPIO_Init(GPIOH, &GPIO_InitStruct);

  /*Configure GPIO pins : FRAME_RATE_Pin RENDER_TIME_Pin */
  GPIO_InitStruct.Pin = FRAME_RATE_Pin|RENDER_TIME_Pin;
  GPIO_InitStruct.Mode = GPIO_MODE_OUTPUT_PP;
  GPIO_InitStruct.Pull = GPIO_NOPULL;
  GPIO_InitStruct.Speed = GPIO_SPEED_FREQ_VERY_HIGH;
  HAL_GPIO_Init(GPIOC, &GPIO_InitStruct);

  /*Configure GPIO pin : PSU_EN_1V1____D4_Pin */
  GPIO_InitStruct.Pin = PSU_EN_1V1____D4_Pin;
  GPIO_InitStruct.Mode = GPIO_MODE_OUTPUT_PP;
  GPIO_InitStruct.Pull = GPIO_NOPULL;
  GPIO_InitStruct.Speed = GPIO_SPEED_FREQ_LOW;
  HAL_GPIO_Init(PSU_EN_1V1____D4_GPIO_Port, &GPIO_InitStruct);

  /*Configure GPIO pin : MCU_ACTIVE_Pin */
  GPIO_InitStruct.Pin = MCU_ACTIVE_Pin;
  GPIO_InitStruct.Mode = GPIO_MODE_OUTPUT_PP;
  GPIO_InitStruct.Pull = GPIO_NOPULL;
  GPIO_InitStruct.Speed = GPIO_SPEED_FREQ_VERY_HIGH;
  HAL_GPIO_Init(MCU_ACTIVE_GPIO_Port, &GPIO_InitStruct);

  /*Configure GPIO pins : ULP_TH_Pin ULP_RSTn_Pin ULP_ENb_Pin */
  GPIO_InitStruct.Pin = ULP_TH_Pin|ULP_RSTn_Pin|ULP_ENb_Pin;
  GPIO_InitStruct.Mode = GPIO_MODE_OUTPUT_PP;
  GPIO_InitStruct.Pull = GPIO_NOPULL;
  GPIO_InitStruct.Speed = GPIO_SPEED_FREQ_LOW;
  HAL_GPIO_Init(GPIOF, &GPIO_InitStruct);

  /*Configure GPIO pin : WAKEUP_Pin */
  GPIO_InitStruct.Pin = WAKEUP_Pin;
  GPIO_InitStruct.Mode = GPIO_MODE_INPUT;
  GPIO_InitStruct.Pull = GPIO_NOPULL;
  HAL_GPIO_Init(WAKEUP_GPIO_Port, &GPIO_InitStruct);

  /*Configure GPIO pin : PB15 */
  GPIO_InitStruct.Pin = GPIO_PIN_15;
  GPIO_InitStruct.Mode = GPIO_MODE_OUTPUT_PP;
  GPIO_InitStruct.Pull = GPIO_NOPULL;
  GPIO_InitStruct.Speed = GPIO_SPEED_FREQ_LOW;
  HAL_GPIO_Init(GPIOB, &GPIO_InitStruct);

}

void ESP_LPW_Task(void *argument)
{
  /* USER CODE BEGIN 5 */

	psee_esp_lpw_task();

  /* USER CODE END 5 */
}

void Task_Update_Fb(void *argument)
{
  /* USER CODE BEGIN Task_Update_Fb */
	const args_update_fb_t *args = (args_update_fb_t *) argument;
	task_update_fb(args);

  /* USER CODE END Task_Update_Fb */
}

void Event_Decoding_Task(void *argument)
{
  /* USER CODE BEGIN Event_Decoding_Task */
	task_evt_decoder((args_evt_decoder_t *) argument);

  /* USER CODE END Event_Decoding_Task */
}

void Activity_Map_Task(void *argument)
{
  /* USER CODE BEGIN Activity_Map_Task */

	psee_activity_map_task();

  /* USER CODE END Activity_Map_Task */
}

void Statistics_Task(void *argument)
{
  /* USER CODE BEGIN Statistics_Task */

	psee_statistics_task();

  /* USER CODE END Statistics_Task */
}

void Led_Tracking_Task(void *argument)
{
  /* USER CODE BEGIN Led_Tracking_Task */

	psee_led_tracking_task();

  /* USER CODE END Led_Tracking_Task */
}

/* MPU Configuration */

void MPU_Config(void)
{
  MPU_Region_InitTypeDef MPU_InitStruct = {0};

  /* Disables the MPU */
  HAL_MPU_Disable();

  /** Initializes and configures the Region and the memory to be protected
  */
  MPU_InitStruct.Enable = MPU_REGION_ENABLE;
  MPU_InitStruct.Number = MPU_REGION_NUMBER0;
  MPU_InitStruct.BaseAddress = 0x90000000;
  MPU_InitStruct.Size = MPU_REGION_SIZE_256MB;
  MPU_InitStruct.SubRegionDisable = 0x0;
  MPU_InitStruct.TypeExtField = MPU_TEX_LEVEL0;
  MPU_InitStruct.AccessPermission = MPU_REGION_FULL_ACCESS;
  MPU_InitStruct.DisableExec = MPU_INSTRUCTION_ACCESS_ENABLE;
  MPU_InitStruct.IsShareable = MPU_ACCESS_NOT_SHAREABLE;
  MPU_InitStruct.IsCacheable = MPU_ACCESS_NOT_CACHEABLE;
  MPU_InitStruct.IsBufferable = MPU_ACCESS_NOT_BUFFERABLE;

  HAL_MPU_ConfigRegion(&MPU_InitStruct);

  /** Initializes and configures the Region and the memory to be protected
  */
  MPU_InitStruct.Number = MPU_REGION_NUMBER1;
  MPU_InitStruct.Size = MPU_REGION_SIZE_16MB;
  MPU_InitStruct.IsCacheable = MPU_ACCESS_CACHEABLE;

  HAL_MPU_ConfigRegion(&MPU_InitStruct);
  /* Enables the MPU */
  HAL_MPU_Enable(MPU_PRIVILEGED_DEFAULT);

}

void HAL_TIM_PeriodElapsedCallback(TIM_HandleTypeDef *htim)
{
  if (htim->Instance == TIM6) {
    HAL_IncTick();
  }
}

void Error_Handler(void)
{
}

#ifdef  USE_FULL_ASSERT
/**
  * @brief  Reports the name of the source file and the source line number
  *         where the assert_param error has occurred.
  * @param  file: pointer to the source file name
  * @param  line: assert_param error line source number
  * @retval None
  */
void assert_failed(uint8_t *file, uint32_t line)
{
  /* USER CODE BEGIN 6 */
	/* User can add his own implementation to report the file name and line number,
     tex: // printf("Wrong parameters value: file %s on line %d\r\n", file, line) */
  /* USER CODE END 6 */
}
#endif /* USE_FULL_ASSERT */
